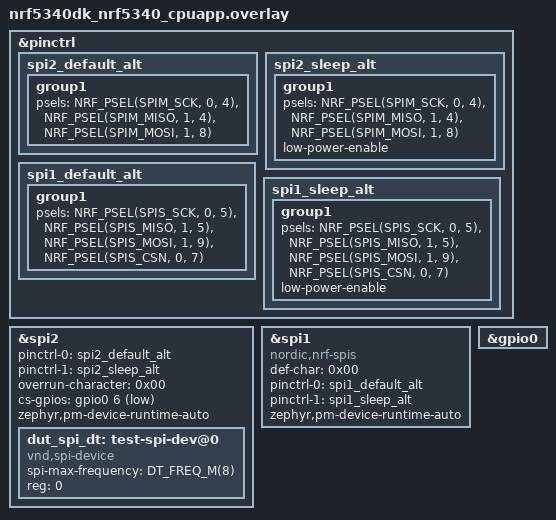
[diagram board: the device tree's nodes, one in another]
/*
 * Copyright (c) 2026 Nordic Semiconductor
 *
 * SPDX-License-Identifier: Apache-2.0
 */

&pinctrl {
	spi2_default_alt: spi2_default_alt {
		group1 {
			psels = <NRF_PSEL(SPIM_SCK, 0, 4)>,
				<NRF_PSEL(SPIM_MISO, 1, 4)>,
				<NRF_PSEL(SPIM_MOSI, 1, 8)>;
		};
	};

	spi2_sleep_alt: spi2_sleep_alt {
		group1 {
			psels = <NRF_PSEL(SPIM_SCK, 0, 4)>,
				<NRF_PSEL(SPIM_MISO, 1, 4)>,
				<NRF_PSEL(SPIM_MOSI, 1, 8)>;
			low-power-enable;
		};
	};

	spi1_default_alt: spi1_default_alt {
		group1 {
			psels = <NRF_PSEL(SPIS_SCK, 0, 5)>,
				<NRF_PSEL(SPIS_MISO, 1, 5)>,
				<NRF_PSEL(SPIS_MOSI, 1, 9)>,
				<NRF_PSEL(SPIS_CSN, 0, 7)>;
		};
	};

	spi1_sleep_alt: spi1_sleep_alt {
		group1 {
			psels = <NRF_PSEL(SPIS_SCK, 0, 5)>,
				<NRF_PSEL(SPIS_MISO, 1, 5)>,
				<NRF_PSEL(SPIS_MOSI, 1, 9)>,
				<NRF_PSEL(SPIS_CSN, 0, 7)>;
			low-power-enable;
		};
	};
};

&spi2 {
	status = "okay";
	pinctrl-0 = <&spi2_default_alt>;
	pinctrl-1 = <&spi2_sleep_alt>;
	pinctrl-names = "default", "sleep";
	overrun-character = <0x00>;
	cs-gpios = <&gpio0 6 GPIO_ACTIVE_LOW>;
	zephyr,pm-device-runtime-auto;

	dut_spi_dt: test-spi-dev@0 {
		compatible = "vnd,spi-device";
		spi-max-frequency = <DT_FREQ_M(8)>;
		reg = <0>;
	};
};

dut_spis: &spi1 {
	compatible = "nordic,nrf-spis";
	status = "okay";
	def-char = <0x00>;
	pinctrl-0 = <&spi1_default_alt>;
	pinctrl-1 = <&spi1_sleep_alt>;
	pinctrl-names = "default", "sleep";
	zephyr,pm-device-runtime-auto;
};

&gpio0 {
	status = "okay";
};
